# CY8C5888LTI_LP097 register map
File version: 0.1
CY8C58LP
Registers are 32-bit, read-write, no defined reset value unless marked. A register's access mark holds for its fields unless they carry their own. Offsets are from the block's base; lines under a group give offsets from that group; [hi:lo] are bit positions; {n}, {i} and the like mark numbered series; 'fields as' and 'values as' point back to an identical list; <NAME> marks a mode.

## Memory map
0x00000000 Encoder_Right
0x00000000 leftEncTimer
0x00000000 rightEncTimer
0x00000000 ADC_SAR_1 — SAR ADC
0x00000000 UART_1 — UART
0x00000000 CAN_1
0x00000000 Encoder_Left

## Encoder_Right
Base 0x00000000
0x4000640A Encoder_Right_COUNTER 16-bit — UDB.A0 - Current Counter Value
0x4000642A Encoder_Right_PERIOD 16-bit — UDB.D0 - Assigned Period
0x4000643A Encoder_Right_COMPARE 16-bit — UDB.D1 - Assigned Compare Value
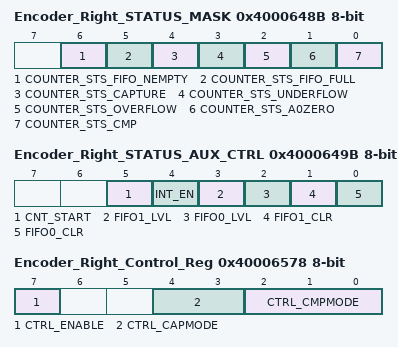
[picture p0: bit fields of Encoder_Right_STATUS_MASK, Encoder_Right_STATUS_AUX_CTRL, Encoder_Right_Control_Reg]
0x4000648B Encoder_Right_STATUS_MASK 8-bit — UDB Status bits Interrupt Mask Enable Register
  [6] COUNTER_STS_FIFO_NEMPTY — FIFO Not Empty Status
  [5] COUNTER_STS_FIFO_FULL — FIFO Full Status
  [4] COUNTER_STS_CAPTURE — Capture Status
  [3] COUNTER_STS_UNDERFLOW — Underflow status
  [2] COUNTER_STS_OVERFLOW — Overflow status
  [1] COUNTER_STS_A0ZERO — A0 Zero ouput status
  [0] COUNTER_STS_CMP — Compare output status
0x4000649B Encoder_Right_STATUS_AUX_CTRL 8-bit — UDB Auxilliary Control Register
  [5] CNT_START — FIFO0 clear
    0=E_CNT_START0 (Disable counter); 1=E_CNT_START1 (Enable counter)
  [4] INT_EN
    0=E_INT_EN0 (Interrupt disabled); 1=E_INT_EN1 (Interrupt enabled)
  [3] FIFO1_LVL — FIFO level
    0=E_FIFO_LVL_0 (FIFO LVL: input mode: FIFO not full; output mode: FIFO not empty); 1=E_FIFO_LVL_1 (FIFO LVL: input mode: FIFO at least 1/2 empty; output mode: FIFO at least 1/2 full)
  [2] FIFO0_LVL — FIFO level
    values as FIFO1_LVL
  [1] FIFO1_CLR — FIFO1 clear
    0=E_FIFO_CLR_0 (Normal FIFO operation); 1=E_FIFO_CLR_1 (Clear FIFO state)
  [0] FIFO0_CLR — FIFO0 clear
    values as FIFO1_CLR
0x40006578 Encoder_Right_Control_Reg 8-bit — UDB Control Register - Assigned Control Register Value
  [7] CTRL_ENABLE — Enable Counter
  [4:3] CTRL_CAPMODE — Capture mode
  [2:0] CTRL_CMPMODE — Compare mode

## leftEncTimer
Base 0x00000000
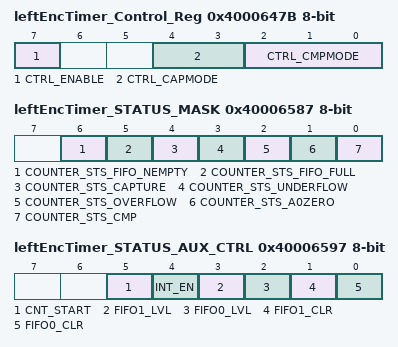
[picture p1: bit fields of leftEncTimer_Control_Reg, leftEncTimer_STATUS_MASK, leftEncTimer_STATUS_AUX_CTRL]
0x4000647B leftEncTimer_Control_Reg 8-bit — UDB Control Register - Assigned Control Register Value
  [7] CTRL_ENABLE — Enable Counter
  [4:3] CTRL_CAPMODE — Capture mode
  [2:0] CTRL_CMPMODE — Compare mode
0x40006506 leftEncTimer_COUNTER 16-bit — UDB.A0 - Current Counter Value
0x40006526 leftEncTimer_PERIOD 16-bit — UDB.D0 - Assigned Period
0x40006536 leftEncTimer_COMPARE 16-bit — UDB.D1 - Assigned Compare Value
0x40006587 leftEncTimer_STATUS_MASK 8-bit — UDB Status bits Interrupt Mask Enable Register
  [6] COUNTER_STS_FIFO_NEMPTY — FIFO Not Empty Status
  [5] COUNTER_STS_FIFO_FULL — FIFO Full Status
  [4] COUNTER_STS_CAPTURE — Capture Status
  [3] COUNTER_STS_UNDERFLOW — Underflow status
  [2] COUNTER_STS_OVERFLOW — Overflow status
  [1] COUNTER_STS_A0ZERO — A0 Zero ouput status
  [0] COUNTER_STS_CMP — Compare output status
0x40006597 leftEncTimer_STATUS_AUX_CTRL 8-bit — UDB Auxilliary Control Register
  [5] CNT_START — FIFO0 clear
    0=E_CNT_START0 (Disable counter); 1=E_CNT_START1 (Enable counter)
  [4] INT_EN
    0=E_INT_EN0 (Interrupt disabled); 1=E_INT_EN1 (Interrupt enabled)
  [3] FIFO1_LVL — FIFO level
    0=E_FIFO_LVL_0 (FIFO LVL: input mode: FIFO not full; output mode: FIFO not empty); 1=E_FIFO_LVL_1 (FIFO LVL: input mode: FIFO at least 1/2 empty; output mode: FIFO at least 1/2 full)
  [2] FIFO0_LVL — FIFO level
    values as FIFO1_LVL
  [1] FIFO1_CLR — FIFO1 clear
    0=E_FIFO_CLR_0 (Normal FIFO operation); 1=E_FIFO_CLR_1 (Clear FIFO state)
  [0] FIFO0_CLR — FIFO0 clear
    values as FIFO1_CLR

## rightEncTimer
Base 0x00000000
0x40006504 rightEncTimer_COUNTER 16-bit — UDB.A0 - Current Counter Value
0x40006524 rightEncTimer_PERIOD 16-bit — UDB.D0 - Assigned Period
0x40006534 rightEncTimer_COMPARE 16-bit — UDB.D1 - Assigned Compare Value
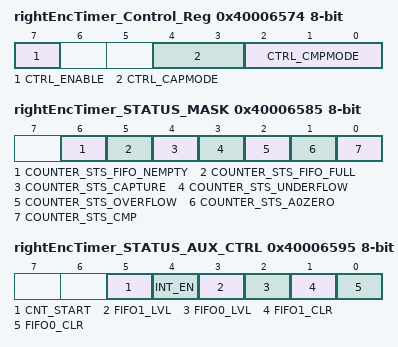
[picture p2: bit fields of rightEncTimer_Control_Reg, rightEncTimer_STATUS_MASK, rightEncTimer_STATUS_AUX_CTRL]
0x40006574 rightEncTimer_Control_Reg 8-bit — UDB Control Register - Assigned Control Register Value
  [7] CTRL_ENABLE — Enable Counter
  [4:3] CTRL_CAPMODE — Capture mode
  [2:0] CTRL_CMPMODE — Compare mode
0x40006585 rightEncTimer_STATUS_MASK 8-bit — UDB Status bits Interrupt Mask Enable Register
  [6] COUNTER_STS_FIFO_NEMPTY — FIFO Not Empty Status
  [5] COUNTER_STS_FIFO_FULL — FIFO Full Status
  [4] COUNTER_STS_CAPTURE — Capture Status
  [3] COUNTER_STS_UNDERFLOW — Underflow status
  [2] COUNTER_STS_OVERFLOW — Overflow status
  [1] COUNTER_STS_A0ZERO — A0 Zero ouput status
  [0] COUNTER_STS_CMP — Compare output status
0x40006595 rightEncTimer_STATUS_AUX_CTRL 8-bit — UDB Auxilliary Control Register
  [5] CNT_START — FIFO0 clear
    0=E_CNT_START0 (Disable counter); 1=E_CNT_START1 (Enable counter)
  [4] INT_EN
    0=E_INT_EN0 (Interrupt disabled); 1=E_INT_EN1 (Interrupt enabled)
  [3] FIFO1_LVL — FIFO level
    0=E_FIFO_LVL_0 (FIFO LVL: input mode: FIFO not full; output mode: FIFO not empty); 1=E_FIFO_LVL_1 (FIFO LVL: input mode: FIFO at least 1/2 empty; output mode: FIFO at least 1/2 full)
  [2] FIFO0_LVL — FIFO level
    values as FIFO1_LVL
  [1] FIFO1_CLR — FIFO1 clear
    0=E_FIFO_CLR_0 (Normal FIFO operation); 1=E_FIFO_CLR_1 (Clear FIFO state)
  [0] FIFO0_CLR — FIFO0 clear
    values as FIFO1_CLR
